# ICSSM_ICSSM_PR1_MII_RT_PR1_MII_RT_G_CFG_REGS_G_48033000h register map
Vendor: Texas Instruments
Peripheral module from a debugger description file (folder AM261x).
Registers are 32-bit, read-only, reset 0x0 unless marked. A register's access mark holds for its fields unless they carry their own. Offsets are as the file gives them; lines under a group give offsets from that group; [hi:lo] are bit positions; {n}, {i} and the like mark numbered series; 'fields as' and 'values as' point back to an identical list; <NAME> marks a mode.

## ICSSM_PR1_MII_RT_PR1_MII_RT_G_CFG_REGS_G
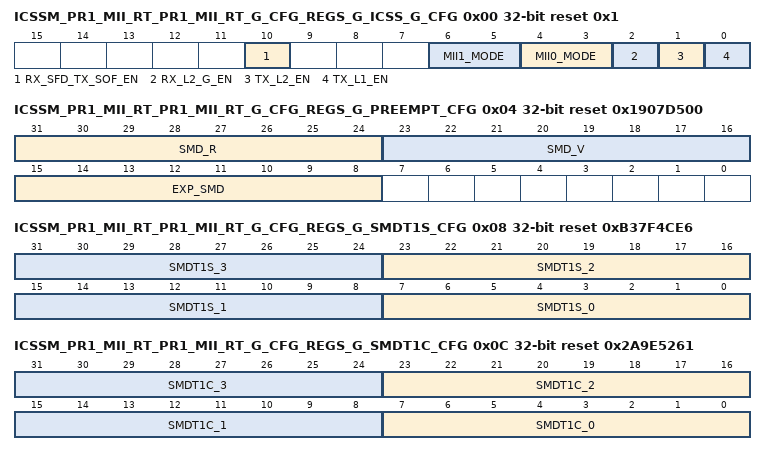
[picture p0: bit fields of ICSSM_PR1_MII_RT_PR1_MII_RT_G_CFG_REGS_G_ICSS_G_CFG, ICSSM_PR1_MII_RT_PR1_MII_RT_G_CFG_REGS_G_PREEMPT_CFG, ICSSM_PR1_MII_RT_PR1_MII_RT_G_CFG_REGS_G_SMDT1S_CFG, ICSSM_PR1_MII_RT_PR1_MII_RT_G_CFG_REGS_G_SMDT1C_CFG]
0x00 ICSSM_PR1_MII_RT_PR1_MII_RT_G_CFG_REGS_G_ICSS_G_CFG rw reset 0x1 — ICSS_G Ethernet Cfg.
  [10] RX_SFD_TX_SOF_EN — Enable the remaping of tx_sof to rx_sfd if auto fwd is enable
  [6:5] MII1_MODE — MII1 MODE 0:MII1:RGMII2:SGMII
  [4:3] MII0_MODE — MII0 MODE 0:MII1:RGMII2:SGMII
  [2] RX_L2_G_EN — Enable the RX L2 G features of filter frags of size TBD and backpressure RX L20:Disabled1:Enabled
  [1] TX_L2_EN — Enable the TX L2 Fifo0:Disabled1:Enabled
  [0] TX_L1_EN — Enable the TX L1 Fifo0:Disabled1:Enabled
0x04 ICSSM_PR1_MII_RT_PR1_MII_RT_G_CFG_REGS_G_PREEMPT_CFG rw reset 0x1907D500
  [31:24] SMD_R — Response frame TAG
  [23:16] SMD_V — Verification frame TAG
  [15:8] EXP_SMD — None preemptable frame start, or express frame
0x08 ICSSM_PR1_MII_RT_PR1_MII_RT_G_CFG_REGS_G_SMDT1S_CFG rw reset 0xB37F4CE6
  [8n+7:8n] SMDT1S_{n} (n=0..3) — SMDT1S{n} pattern
0x0C ICSSM_PR1_MII_RT_PR1_MII_RT_G_CFG_REGS_G_SMDT1C_CFG rw reset 0x2A9E5261
  [8n+7:8n] SMDT1C_{n} (n=0..3) — SMDT1C{n} pattern
0x10 ICSSM_PR1_MII_RT_PR1_MII_RT_G_CFG_REGS_G_POOL_PTR_CFG rw reset 0x800
  [15:0] MAX_PKT_SIZE — Max Pkt Size, used in pool ptr logic for wrap around
0x14 ICSSM_PR1_MII_RT_PR1_MII_RT_G_CFG_REGS_G_TX_EARLY_EOF access not given reset not defined
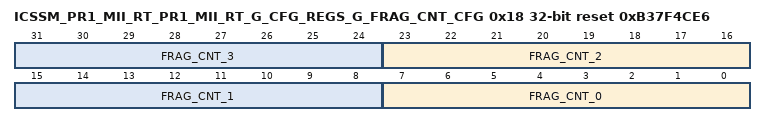
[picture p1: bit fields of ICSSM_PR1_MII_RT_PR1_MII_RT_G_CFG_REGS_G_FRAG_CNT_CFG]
0x18 ICSSM_PR1_MII_RT_PR1_MII_RT_G_CFG_REGS_G_FRAG_CNT_CFG rw reset 0xB37F4CE6
  [8n+7:8n] FRAG_CNT_{n} (n=0..3) — FRAG Cnt{n} pattern
{0xD00+4i} ICSSM_PR1_MII_RT_PR1_MII_RT_G_CFG_REGS_G_QUEUE{i} rw (i=0..31)
  [15:0] QUEUE_H_PTR{i} — Queue {i}
{0xE00+4i} ICSSM_PR1_MII_RT_PR1_MII_RT_G_CFG_REGS_G_QUEUE_PEEK{i} (i=0..15)
  [15:0] QUEUE_H_PEEK_PTR{i} — Queue {i} Peek portal
{0xE40+4i} ICSSM_PR1_MII_RT_PR1_MII_RT_G_CFG_REGS_G_QUEUE_CNT{i} (i=0..31)
  [15:0] QUEUE_CNT_ENTRIES_{i} — Queue Entry Count{i}
0xF40 ICSSM_PR1_MII_RT_PR1_MII_RT_G_CFG_REGS_G_QUEUE_RESET rw
  [5:0] RESET_QUEUE_ID
